# RS14100 register map
File version: 1.0
CPU: CM4 r0p1, little endian, MPU, FPU, 4 interrupt priority bits
Registers are 32-bit, read-write, reset 0x0 unless marked. A register's access mark holds for its fields unless they carry their own. Offsets are from the block's base; [hi:lo] are bit positions; 'fields as' and 'values as' point back to an identical list.

## SCT0 — Configurable timer is used in counting clocks, events and states with reference clock external clock and system clock
Base 0x45060000
Same registers: SCT1 0x45060100, SCT2 0x45060200, SCT3 0x45060300
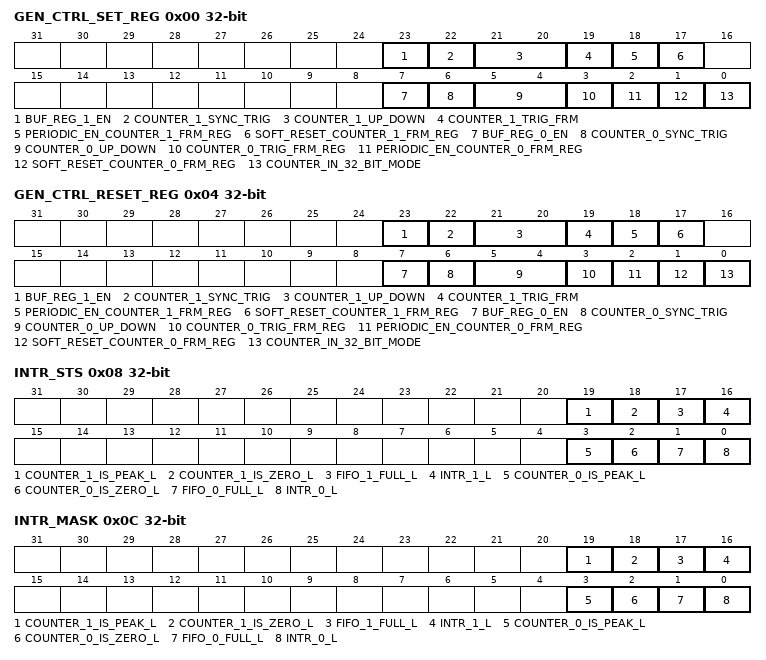
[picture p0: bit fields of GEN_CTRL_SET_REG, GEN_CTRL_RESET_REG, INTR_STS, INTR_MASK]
0x00 GEN_CTRL_SET_REG — General control set register
  [23] BUF_REG_1_EN — Buffer register gets enabled for MATCH REG. MATCH_BUF_REG is always available and whenever this bit is set only, gets copied to MATCH REG.
    0=Disable (If Write: No effect If Read:Buffer is not enabled and not in path.); 1=Enable (If Write:Buffer will be enabled and in path If Read:Buffer is enabled and in path)
  [22] COUNTER_1_SYNC_TRIG — This is applied to 32 bits of counter only when the counter is in 32 bit counter mode otherwise this will be applied to only lower 16 bits of counter. This enables the counter to run/active when sync is found.
    0=Disable (If Write: No effect If Read:Read should always return 0); 1=Enable (If Write:Counter_1 will be active. If Read:Read should always return 0)
  [21:20] COUNTER_1_UP_DOWN — This enables the counter to run in upward direction
    0=If Write:No effect If Read:Counter_1 is in down-up counting mode; 1=If Write:Counter_1 will be up-counting If Read:Counter_1 is in up-counting mode; 2=If Write:Counter down direction enable If Read:Counter_1 is in down counting mode; 3=If Write:Both up and down directions enable. If Read:Counter_1 is in up-down counting mode
  [19] COUNTER_1_TRIG_FRM — This enables the counter to run/active
    0=Disable (If Write:No effect If Read:Always should return 0); 1=Enable (If Write:Counter_1 will be active If Read:Always should return 0)
  [18] PERIODIC_EN_COUNTER_1_FRM_REG — This resets the counter on the write
    0=Disable (If Write:No effect If Read:Counter_1 is not in periodic mode); 1=Enable (If Write:Counter_1 will be in periodic mode If Read:Counter_1 is in periodic mode)
  [17] SOFT_RESET_COUNTER_1_FRM_REG — This resets the counter on the write
    0=Disable (If Write:No effect If Read:Always should return 0); 1=Enable (If Write:Counter_1 will be reset If Read:Always should return 0)
  [7] BUF_REG_0_EN — Buffer register gets enabled for MATCH REG. MATCH_BUF_REG is always available and whenever this bit is set only, gets copied to MATCH REG.
    values as BUF_REG_1_EN
  [6] COUNTER_0_SYNC_TRIG — This is applied to 32 bits of counter only when the counter is in 32 bit counter mode otherwise this will be applied to only lower 16 bits of counter. This enables the counter to run/active when sync is found.
    0=Disable (If Write: No effect If Read:Read should always return 0); 1=Enable (If Write:Counter_0 will be active. If Read:Read should always return 0)
  [5:4] COUNTER_0_UP_DOWN — This enables the counter to run in up/down/up-down/down-up directions
    0=If Write:No effect If Read:Counter_0 is in down-up counting mode; 1=If Write:Counter_0 will be up-counting If Read:Counter_0 is in up-counting mode; 2=If Write:Counter down direction enable If Read:Counter_0 is in down counting mode; 3=If Write:Both up and down directions enable. If Read:Counter_0 is in up-down counting mode
  [3] COUNTER_0_TRIG_FRM_REG — This enables the counter to run/active
    0=Disable (If Write: No effect If Read:Read should always return 0); 1=Enable (If Write:Counter_1 will be active If Read:Read should always return 0)
  [2] PERIODIC_EN_COUNTER_0_FRM_REG — This is applied to 32 bits of counter only when the counter is in 32 bit counter mode otherwise this will be applied to only lower 16 bits of counter
    0=Disable (If Write: No effect If Read: Counter_1 is not in periodic mode); 1=Enable (If Write: Counter_1 will be in periodic mode If Read: Counter_1 is in periodic mode)
  [1] SOFT_RESET_COUNTER_0_FRM_REG — This is applied to 32 bits of counter only when the counter is in 32 bit counter mode otherwise this will be applied to only lower 16 bits of counter
    0=Disable (If Write: No effect If Read: Always should return 0); 1=Enable (If Write: Counter_1 will be reset If Read: Always should return 0)
  [0] COUNTER_IN_32_BIT_MODE — Counter_1 and Counter_0 will be merged and used as a single 32 bit counter
    0=Disable (If Write: Counter will be 32 bit mode If Read: Counter is in two 16 bit mode); 1=Enable (If Write: Counter will be 32 bit mode If Read: Counter is in two 16 bit mode)
0x04 GEN_CTRL_RESET_REG — General control reset register
  fields as GEN_CTRL_SET_REG
0x08 INTR_STS ro — Interrupt status
  [19] COUNTER_1_IS_PEAK_L — Counter 1 hit peak (MATCH) in active mode.
  [18] COUNTER_1_IS_ZERO_L — Counter 1 hit zero in active mode.
  [17] FIFO_1_FULL_L — Indicates the FIFO full signal of channel-1
  [16] INTR_1_L — Indicates the FIFO full signal of channel-1
  [3] COUNTER_0_IS_PEAK_L — Counter 0 hit peak (MATCH) in active mode.
  [2] COUNTER_0_IS_ZERO_L — Counter 0 hit zero in active mode.
  [1] FIFO_0_FULL_L — Indicates the FIFO full signal of channel-0
  [0] INTR_0_L — Indicates the FIFO full signal of channel-0
0x0C INTR_MASK reset not defined — Interrupts mask
  [all] fields
    0=Disable (If Write: No effect If Read:Interrupt is masked.); 1=Enable (If Write: Interrupt will be masked. If Read: Interrupt is unmasked.)
  [19] COUNTER_1_IS_PEAK_L — Interrupt mask signal.
  [18] COUNTER_1_IS_ZERO_L — Interrupt mask signal.
  [17] FIFO_1_FULL_L — Interrupt mask signal.
  [16] INTR_1_L — Interrupt mask signal.
  [3] COUNTER_0_IS_PEAK_L — Interrupt mask signal.
  [2] COUNTER_0_IS_ZERO_L — Interrupt mask signal.
  [1] FIFO_0_FULL_L — Interrupt mask signal.
  [0] INTR_0_L — Interrupt mask signal.
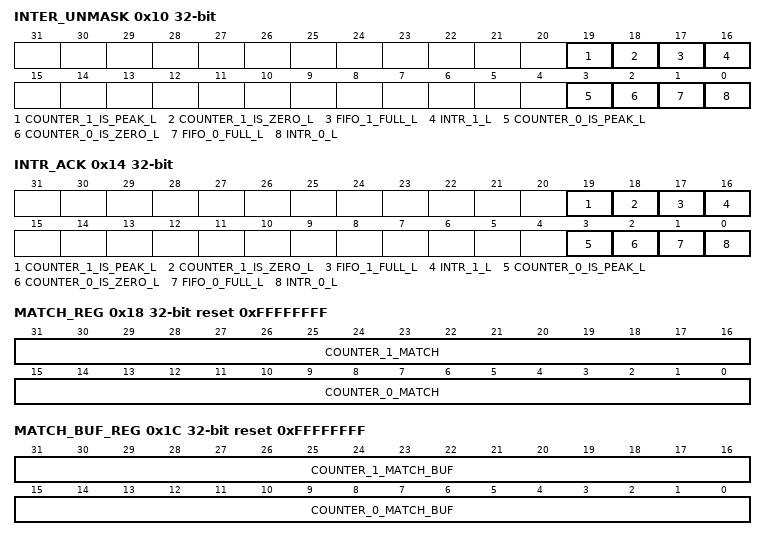
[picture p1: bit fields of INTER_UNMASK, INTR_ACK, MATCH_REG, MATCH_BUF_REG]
0x10 INTER_UNMASK reset not defined — Interrupts unmask
  [all] fields
    0=Disable (If Write: No effect If Read:Interrupt is masked.); 1=Enable (If Write: Interrupt will be unmasked. If Read: Interrupt is unmasked.)
  [19] COUNTER_1_IS_PEAK_L — Interrupt unmask signal.
  [18] COUNTER_1_IS_ZERO_L — Interrupt unmask signal.
  [17] FIFO_1_FULL_L — Interrupt unmask signal.
  [16] INTR_1_L — Interrupt unmask signal.
  [3] COUNTER_0_IS_PEAK_L — Interrupt unmask signal.
  [2] COUNTER_0_IS_ZERO_L — Interrupt unmask signal.
  [1] FIFO_0_FULL_L — Interrupt unmask signal.
  [0] INTR_0_L — Interrupt unmask signal.
0x14 INTR_ACK reset not defined — Interrupt clear/ack register
  [all] fields
    0=Disable (If Write: No effect. If Read: should be returned as this is self clear bit); 1=Enable (If Write: Interrupt will be de asserted.)
  [19] COUNTER_1_IS_PEAK_L — Interrupt ack signal.
  [18] COUNTER_1_IS_ZERO_L — Interrupt ack signal.
  [17] FIFO_1_FULL_L — Interrupt ack signal.
  [16] INTR_1_L — Interrupt ack signal.
  [3] COUNTER_0_IS_PEAK_L — Interrupt ack signal.
  [2] COUNTER_0_IS_ZERO_L — Interrupt ack signal.
  [1] FIFO_0_FULL_L — Interrupt ack signal.
  [0] INTR_0_L — Interrupt ack signal.
0x18 MATCH_REG reset 0xFFFFFFFF — Match value register
  [31:16] COUNTER_1_MATCH — This will be used as upper match
  [15:0] COUNTER_0_MATCH — This will be used as lower match
0x1C MATCH_BUF_REG reset 0xFFFFFFFF — Match Buffer register
  [31:16] COUNTER_1_MATCH_BUF — This gets copied to MATCH register if bug_reg_1_en is set. Copying is done when counter 1 is active and hits 0.
  [15:0] COUNTER_0_MATCH_BUF — This gets copied to MATCH register if bug_reg_0_en is set. Copying is done when counter 0 is active and hits 0.
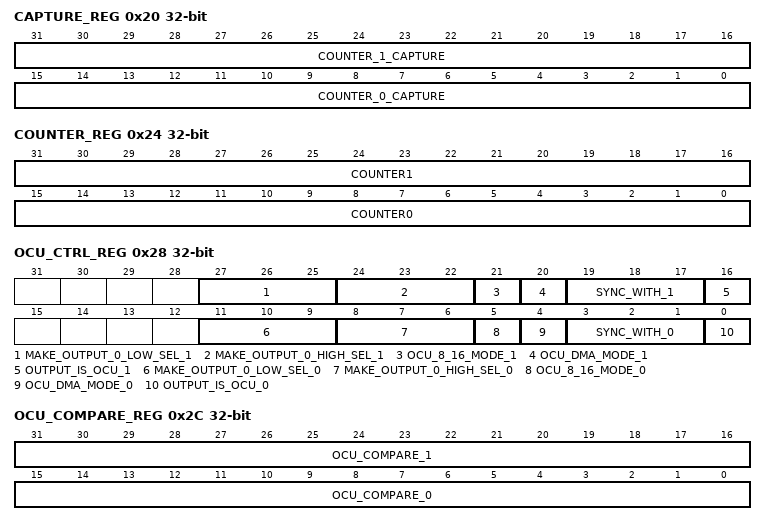
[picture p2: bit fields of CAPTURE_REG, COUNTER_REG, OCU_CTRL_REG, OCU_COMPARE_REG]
0x20 CAPTURE_REG ro — Capture Register
  [31:16] COUNTER_1_CAPTURE — This is a latched value of counter upper part when the selected capture_event occurs
  [15:0] COUNTER_0_CAPTURE — This is a latched value of counter lower part when the selected capture_event occurs
0x24 COUNTER_REG — Counter Register
  [31:16] COUNTER1 ro — This holds the value of counter-1
  [15:0] COUNTER0 ro — This holds the value of counter-0
0x28 OCU_CTRL_REG (reset mask 0x7FFFFF) — OCU control register
  [27:25] MAKE_OUTPUT_0_LOW_SEL_1 — Check counter ocus for possibilities. When this is hit output will be made low.
  [24:22] MAKE_OUTPUT_0_HIGH_SEL_1 — Check counter ocus for possibilities. When this is hit output will be made high.
  [21] OCU_8_16_MODE_1 — Indicates whether entire 16 bits or only 8-bits of the channel 1 are used in OCU mode
  [20] OCU_DMA_MODE_1 — Indicates whether the OCU DMA mode is active or not for channel 1
  [19:17] SYNC_WITH_1 — Indicates whether the other channel is in sync with this channel
  [16] OUTPUT_IS_OCU_1 — Indicates whether the output is in OCU mode or not for channel 1
  [11:9] MAKE_OUTPUT_0_LOW_SEL_0 — Check counter ocus for possibilities. When this is hit output will be made low.
  [8:6] MAKE_OUTPUT_0_HIGH_SEL_0 — Check counter ocus for possibilities. When this is hit output will be made high.
  [5] OCU_8_16_MODE_0 — Indicates whether entire 16 bits or only 8-bits of the channel 0 are used in OCU mode
  [4] OCU_DMA_MODE_0 — Indicates whether the OCU DMA mode is active or not for channel 0
  [3:1] SYNC_WITH_0 — Indicates whether the other channel is in sync with this channel
  [0] OUTPUT_IS_OCU_0 — Indicates whether the output is in OCU mode or not for channel-0
0x2C OCU_COMPARE_REG (reset mask 0xFFFF) — OCU Compare Register
  [31:16] OCU_COMPARE_1 — Holds the threshold value of present OCU period which denotes the number of clock cycles for which the OCU output should be considered (counter 1)
  [15:0] OCU_COMPARE_0 — Holds the threshold value of present OCU period which denotes the number of clock cycles for which the OCU output should be considered (counter 0)
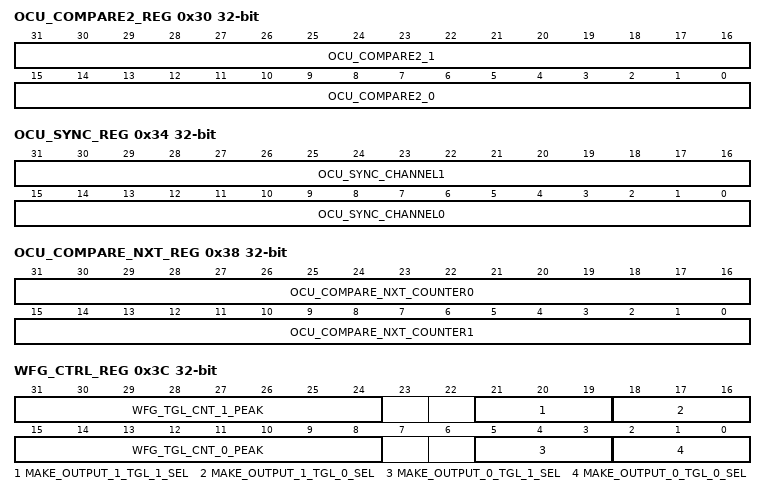
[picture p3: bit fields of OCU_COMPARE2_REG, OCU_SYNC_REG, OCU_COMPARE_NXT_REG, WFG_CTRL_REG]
0x30 OCU_COMPARE2_REG (reset mask 0xFFFF) — OCU Compare2 Register
  [31:16] OCU_COMPARE2_1 — Holds the threshold value of present OCU period2 which denotes the number of clock cycles for which the OCU output should be considered (counter 1)
  [15:0] OCU_COMPARE2_0 — Holds the threshold value of present OCU period2 which denotes the number of clock cycles for which the OCU output should be considered (counter 0)
0x34 OCU_SYNC_REG — OCU Synchronization Register
  [31:16] OCU_SYNC_CHANNEL1 — Starting point of channel 1 for synchronization purpose
  [15:0] OCU_SYNC_CHANNEL0 — Starting point of channel 0 for synchronization purpose
0x38 OCU_COMPARE_NXT_REG — PWM compare next register
  [31:16] OCU_COMPARE_NXT_COUNTER0 — PWM output should be high for counter 0
  [15:0] OCU_COMPARE_NXT_COUNTER1 — OCU output should be high for counter 1
0x3C WFG_CTRL_REG (reset mask 0x7FFFFF) — WFG control register
  [31:24] WFG_TGL_CNT_1_PEAK — WFG mode output toggle count clock for channel 1
  [21:19] MAKE_OUTPUT_1_TGL_1_SEL — Check the counter ocus possibilities for description for channel 1.
  [18:16] MAKE_OUTPUT_1_TGL_0_SEL — Check the counter ocus possibilities for description for channel 1.
  [15:8] WFG_TGL_CNT_0_PEAK — WFG mode output toggle count clock for channel 0.
  [5:3] MAKE_OUTPUT_0_TGL_1_SEL — Check the counter ocus possibilities for description for channel 0.
  [2:0] MAKE_OUTPUT_0_TGL_0_SEL — Check the counter ocus possibilities for description for channel 0.
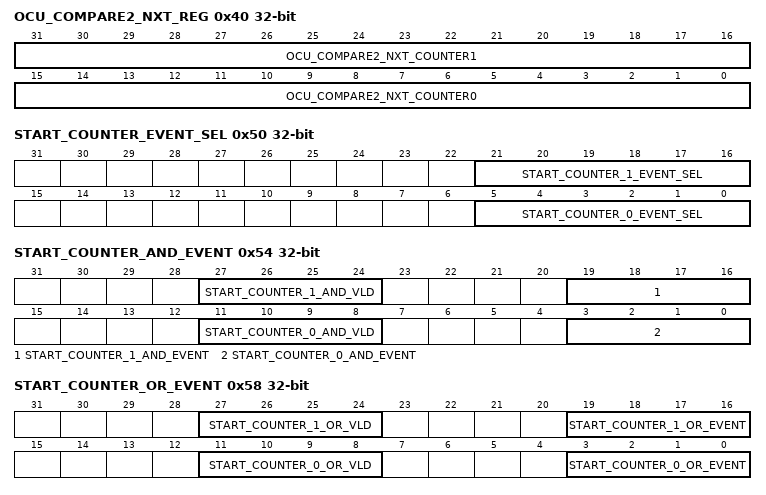
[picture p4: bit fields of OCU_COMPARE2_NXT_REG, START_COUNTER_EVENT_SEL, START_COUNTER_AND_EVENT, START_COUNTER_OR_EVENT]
0x40 OCU_COMPARE2_NXT_REG — PWM compare next register
  [31:16] OCU_COMPARE2_NXT_COUNTER1 — PWM output should be high for counter 0
  [15:0] OCU_COMPARE2_NXT_COUNTER0 — OCU output should be high for counter 1
0x50 START_COUNTER_EVENT_SEL — Start counter event select register
  [21:16] START_COUNTER_1_EVENT_SEL — For two 16 bit counters mode: Event select for starting the Counter 1. For 32 bit counter mode: Invalid. Please refer to events table for description
  [5:0] START_COUNTER_0_EVENT_SEL — For two 16 bit counters mode: Event select for starting the Counter 0 For 32 bit counter mode: Event select for starting counter
0x54 START_COUNTER_AND_EVENT (reset mask 0xF000F)
  [27:24] START_COUNTER_1_AND_VLD
  [19:16] START_COUNTER_1_AND_EVENT — For two 16 bit counters mode: AND expression valids for AND event in start counter event For 32 bit counter mode : Invalid
  [11:8] START_COUNTER_0_AND_VLD
  [3:0] START_COUNTER_0_AND_EVENT — For two 16 bit counter mode: AND expression valids for AND event in start Counter 0 event For 32 bit counter mode AND expression valids for AND event in start counter event
0x58 START_COUNTER_OR_EVENT (reset mask 0xF000F)
  [27:24] START_COUNTER_1_OR_VLD
  [19:16] START_COUNTER_1_OR_EVENT — For two 16 bit counters mode: OR expression valids for OR event in start counter event For 32 bit counter mode : Invalid.
  [11:8] START_COUNTER_0_OR_VLD
  [3:0] START_COUNTER_0_OR_EVENT — For two 16 bit counter mode: OR expression valids for OR event in start Counter 0 event For 32 bit counter mode OR expression valids for OR event in start counter event
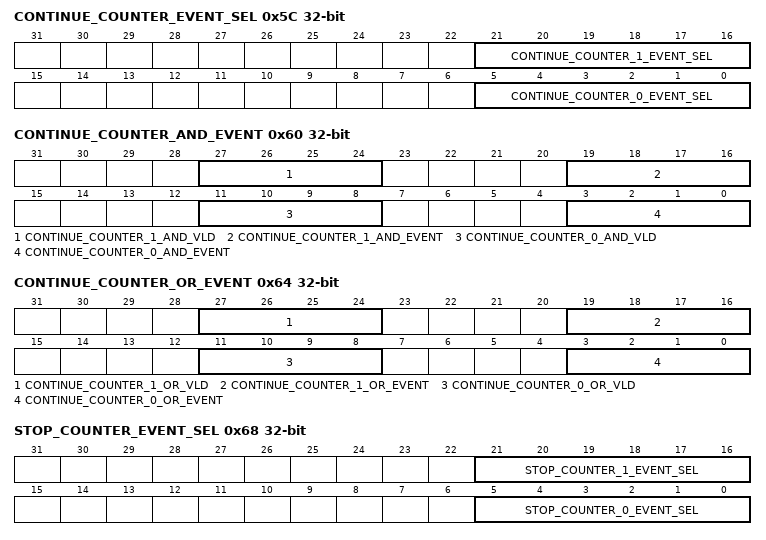
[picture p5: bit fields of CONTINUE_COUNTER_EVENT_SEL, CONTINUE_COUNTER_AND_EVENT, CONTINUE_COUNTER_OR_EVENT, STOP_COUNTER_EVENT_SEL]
0x5C CONTINUE_COUNTER_EVENT_SEL — Continue counter event select register
  [21:16] CONTINUE_COUNTER_1_EVENT_SEL — For two 16 bit counters mode: Event select for continuing the Counter 1 For 32 bit counter mode: Invalid.
  [5:0] CONTINUE_COUNTER_0_EVENT_SEL — For two 16 bit counters mode: Event select for continuing the Counter 0 For 32 bit counter mode: Event select for continuing counter
0x60 CONTINUE_COUNTER_AND_EVENT (reset mask 0xF000F)
  [27:24] CONTINUE_COUNTER_1_AND_VLD
  [19:16] CONTINUE_COUNTER_1_AND_EVENT — For two 16 bit counters mode: AND expression valids for AND event in continue counter event For 32 bit counter mode : Invalid
  [11:8] CONTINUE_COUNTER_0_AND_VLD
  [3:0] CONTINUE_COUNTER_0_AND_EVENT — For two 16 bit counter mode: AND expression valids for AND event in continue Counter 0 event For 32 bit counter mode AND expression valids for AND event in continue counter event.
0x64 CONTINUE_COUNTER_OR_EVENT (reset mask 0xF000F)
  [27:24] CONTINUE_COUNTER_1_OR_VLD
  [19:16] CONTINUE_COUNTER_1_OR_EVENT — For two 16 bit counters mode: OR expression valids for OR event in continue counter event For 32 bit counter mode : Invalid
  [11:8] CONTINUE_COUNTER_0_OR_VLD
  [3:0] CONTINUE_COUNTER_0_OR_EVENT — For two 16 bit counter mode: OR expression valids for OR event in continue Counter 0 event For 32 bit counter mode OR expression valids for OR event in continue counter event
0x68 STOP_COUNTER_EVENT_SEL — Stop counter event select register
  [21:16] STOP_COUNTER_1_EVENT_SEL — For two 16 bit counters mode: Event select for Stopping the Counter 1 For 32 bit counter mode: Invalid
  [5:0] STOP_COUNTER_0_EVENT_SEL — For two 16 bit counters mode: Event select for Stopping the Counter 0 For 32 bit counter mode: Event select for Stopping counter
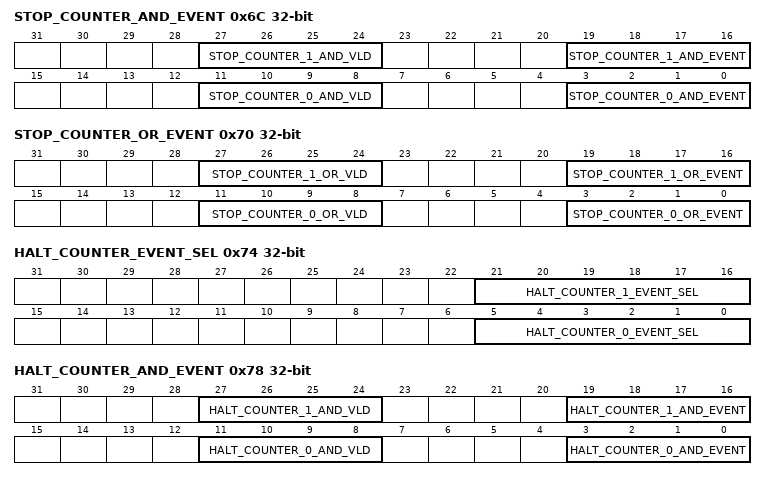
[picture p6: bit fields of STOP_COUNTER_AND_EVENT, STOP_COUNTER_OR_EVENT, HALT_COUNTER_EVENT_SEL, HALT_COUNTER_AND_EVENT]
0x6C STOP_COUNTER_AND_EVENT (reset mask 0xF000F)
  [27:24] STOP_COUNTER_1_AND_VLD
  [19:16] STOP_COUNTER_1_AND_EVENT — For two 16 bit counters mode: AND expression valids for AND event in stop counter event For 32 bit counter mode : Invalid
  [11:8] STOP_COUNTER_0_AND_VLD
  [3:0] STOP_COUNTER_0_AND_EVENT — For two 16 bit counter mode: AND expression valids for AND event in stop Counter 0 event For 32 bit counter mode AND expression valids for AND event in stop counter event
0x70 STOP_COUNTER_OR_EVENT (reset mask 0xF000F)
  [27:24] STOP_COUNTER_1_OR_VLD
  [19:16] STOP_COUNTER_1_OR_EVENT — For two 16 bit counters mode: OR expression valids for OR event in Stop counter event For 32 bit counter mode : Invalid
  [11:8] STOP_COUNTER_0_OR_VLD
  [3:0] STOP_COUNTER_0_OR_EVENT — For two 16 bit counter mode: OR expression valids for OR event in Stop Counter 0 event For 32 bit counter mode OR expression valids for OR event in Stop counter event
0x74 HALT_COUNTER_EVENT_SEL — Halt counter event select register
  [21:16] HALT_COUNTER_1_EVENT_SEL — For two 16 bit counters mode: Event select for Halting the Counter 1 For 32 bit counter mode: Invalid
  [5:0] HALT_COUNTER_0_EVENT_SEL — For two 16 bit counters mode: Event select for Halting the Counter 0 For 32 bit counter mode: Event select for Halting counter
0x78 HALT_COUNTER_AND_EVENT (reset mask 0xF000F)
  [27:24] HALT_COUNTER_1_AND_VLD
  [19:16] HALT_COUNTER_1_AND_EVENT — For two 16 bit counters mode: AND expression valids for AND event in stop counter event For 32 bit counter mode : Invalid
  [11:8] HALT_COUNTER_0_AND_VLD
  [3:0] HALT_COUNTER_0_AND_EVENT — For two 16 bit counter mode: AND expression valids for AND event in stop Counter 0 event For 32 bit counter mode AND expression valids for AND event in stop counter event
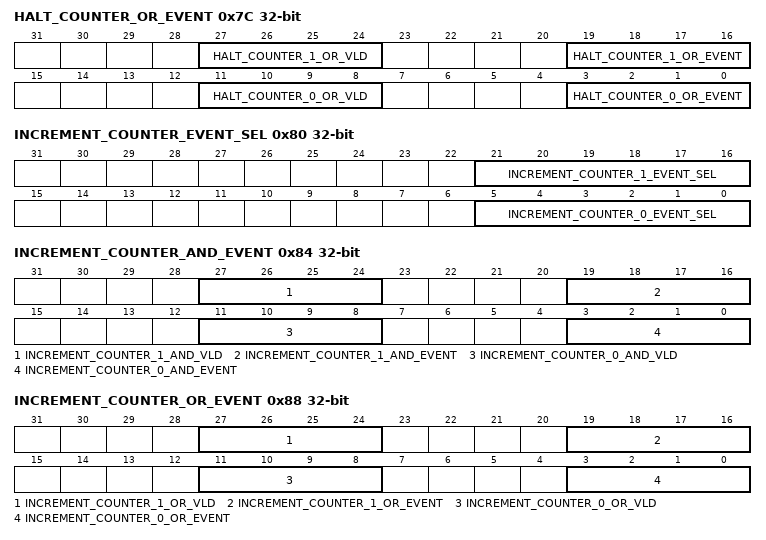
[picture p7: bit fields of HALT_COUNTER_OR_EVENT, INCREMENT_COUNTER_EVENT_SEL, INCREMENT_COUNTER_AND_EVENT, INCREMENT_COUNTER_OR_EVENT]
0x7C HALT_COUNTER_OR_EVENT (reset mask 0xF000F)
  [27:24] HALT_COUNTER_1_OR_VLD
  [19:16] HALT_COUNTER_1_OR_EVENT — For two 16 bit counters mode: OR expression valids for OR event in Halt counter event For 32 bit counter mode : Invalid
  [11:8] HALT_COUNTER_0_OR_VLD
  [3:0] HALT_COUNTER_0_OR_EVENT — For two 16 bit counter mode: OR expression valids for OR event in Halt Counter 0 event For 32 bit counter mode OR expression valids for OR event in Halt counter event
0x80 INCREMENT_COUNTER_EVENT_SEL — Increment counter event select register
  [21:16] INCREMENT_COUNTER_1_EVENT_SEL — For two 16 bit counters mode: Event select for Incrementing the Counter 1 For 32 bit counter mode: Invalid
  [5:0] INCREMENT_COUNTER_0_EVENT_SEL — For two 16 bit counters mode: Event select for Incrementing the Counter 0 For 32 bit counter mode: Event select for Incrementing counter
0x84 INCREMENT_COUNTER_AND_EVENT (reset mask 0xF000F)
  [27:24] INCREMENT_COUNTER_1_AND_VLD
  [19:16] INCREMENT_COUNTER_1_AND_EVENT — For two 16 bit counters mode: AND expression valids for AND event in stop counter event For 32 bit counter mode : Invalid
  [11:8] INCREMENT_COUNTER_0_AND_VLD
  [3:0] INCREMENT_COUNTER_0_AND_EVENT — For two 16 bit counter mode: AND expression valids for AND event in stop Counter 0 event For 32 bit counter mode AND expression valids for AND event in stop counter event
0x88 INCREMENT_COUNTER_OR_EVENT (reset mask 0xF000F)
  [27:24] INCREMENT_COUNTER_1_OR_VLD
  [19:16] INCREMENT_COUNTER_1_OR_EVENT — For two 16 bit counters mode: OR expression valids for OR event in Increment counter event For 32 bit counter mode : Invalid
  [11:8] INCREMENT_COUNTER_0_OR_VLD
  [3:0] INCREMENT_COUNTER_0_OR_EVENT — For two 16 bit counter mode: OR expression valids for OR event in Increment Counter 0 event For 32 bit counter mode OR expression valids for OR event in Increment counter event
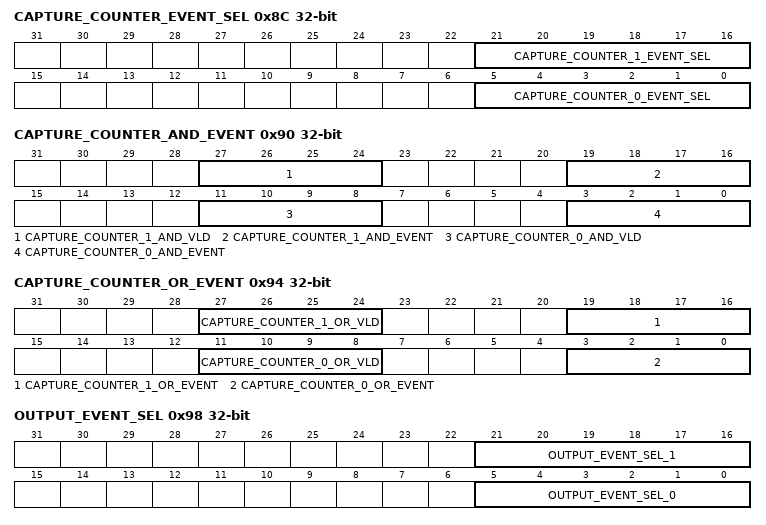
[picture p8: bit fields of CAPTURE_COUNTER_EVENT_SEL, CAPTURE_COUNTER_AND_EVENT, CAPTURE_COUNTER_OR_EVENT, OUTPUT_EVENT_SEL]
0x8C CAPTURE_COUNTER_EVENT_SEL — Capture counter event select register
  [21:16] CAPTURE_COUNTER_1_EVENT_SEL — For two 16 bit counters mode: Event select for Capturing the Counter 1 For 32 bit counter mode : Invalid
  [5:0] CAPTURE_COUNTER_0_EVENT_SEL — For two 16 bit counters mode: Event select for Capturing the Counter 0 For 32 bit counter mode: Event select for Capturing counter
0x90 CAPTURE_COUNTER_AND_EVENT (reset mask 0xF000F)
  [27:24] CAPTURE_COUNTER_1_AND_VLD
  [19:16] CAPTURE_COUNTER_1_AND_EVENT — For two 16 bit counters mode: AND expression valids for AND event in stop counter event For 32 bit counter mode : Invalid
  [11:8] CAPTURE_COUNTER_0_AND_VLD
  [3:0] CAPTURE_COUNTER_0_AND_EVENT — For two 16 bit counter mode: AND expression valids for AND event in stop Counter 0 event For 32 bit counter mode AND expression valids for AND event in stop counter event
0x94 CAPTURE_COUNTER_OR_EVENT (reset mask 0xF000F)
  [27:24] CAPTURE_COUNTER_1_OR_VLD
  [19:16] CAPTURE_COUNTER_1_OR_EVENT — For two 16 bit counters mode: OR expression valids for OR event in Capture counter event For 32 bit counter mode : Invalid
  [11:8] CAPTURE_COUNTER_0_OR_VLD
  [3:0] CAPTURE_COUNTER_0_OR_EVENT — For two 16 bit counter mode: OR expression valids for OR event in Capture Counter 0 event For 32 bit counter mode OR expression valids for OR event in Capture counter event
0x98 OUTPUT_EVENT_SEL — Output event select register
  [21:16] OUTPUT_EVENT_SEL_1 — For two 16 bit counters mode: Event select for output event from counter 1 For 32 bit counter mode : Invalid
  [5:0] OUTPUT_EVENT_SEL_0 — For two 16 bit counters mode: Event select for output event from Counter 0 For 32 bit counter mode: Event select for output event
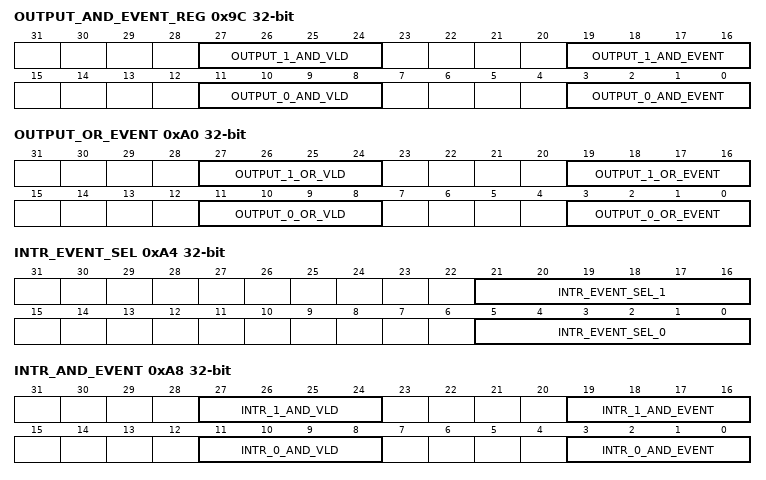
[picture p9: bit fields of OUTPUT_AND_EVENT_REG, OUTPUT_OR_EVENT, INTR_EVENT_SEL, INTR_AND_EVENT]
0x9C OUTPUT_AND_EVENT_REG — Output AND event Register
  [27:24] OUTPUT_1_AND_VLD — AND expression for AND event in output Counter_1 event.
  [19:16] OUTPUT_1_AND_EVENT — AND expression for AND event in output Counter_1 event.
  [11:8] OUTPUT_0_AND_VLD — AND expression for AND event in output Counter_0 event.
  [3:0] OUTPUT_0_AND_EVENT — AND expression for AND event in output Counter_0 event.
0xA0 OUTPUT_OR_EVENT
  [27:24] OUTPUT_1_OR_VLD — Indicates which bits in 3:0 are valid for considering OR event
  [19:16] OUTPUT_1_OR_EVENT — OR expression for OR event in output Counter_0 event
  [11:8] OUTPUT_0_OR_VLD — Indicates which bits in 3:0 are valid for considering OR event
  [3:0] OUTPUT_0_OR_EVENT — OR expression for OR event in output Counter_0 event
0xA4 INTR_EVENT_SEL — Interrupt Event Select Register
  [21:16] INTR_EVENT_SEL_1 — For two 16 bit counters mode: Event select for interrupt event from counter 1 For 32 bit counter mode : Invalid
  [5:0] INTR_EVENT_SEL_0 — For two 16 bit counters mode: Event select for interrupt event from Counter 0 For 32 bit counter mode: Event select for output event
0xA8 INTR_AND_EVENT (reset mask 0x3F003F) — Interrupt AND Event Register
  [27:24] INTR_1_AND_VLD, [19:16] INTR_1_AND_EVENT, [11:8] INTR_0_AND_VLD, [3:0] INTR_0_AND_EVENT
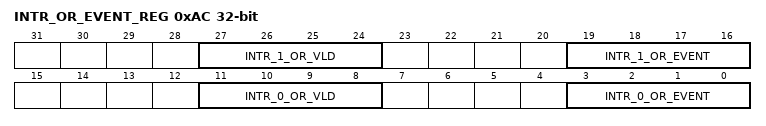
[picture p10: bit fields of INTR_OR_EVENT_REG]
0xAC INTR_OR_EVENT_REG (reset mask 0x3F003F) — Interrupt OR Event Register
  [27:24] INTR_1_OR_VLD, [19:16] INTR_1_OR_EVENT, [11:8] INTR_0_OR_VLD, [3:0] INTR_0_OR_EVENT
